# LPC11Uxx register map
File version: 7
CPU: CM0 r0p0, little endian, no MPU, no FPU, 2 interrupt priority bits
Registers are 32-bit, read-write, reset 0x0 unless marked. A register's access mark holds for its fields unless they carry their own. Offsets are from the block's base; [hi:lo] are bit positions; lines under a group give offsets from that group; {n}, {i} and the like mark numbered series; 'fields as' and 'values as' point back to an identical list.

## GPIO_GROUP_INT0 — GPIO group interrupt
Base 0x4005C000
Same registers: GPIO_GROUP_INT1 0x40060000
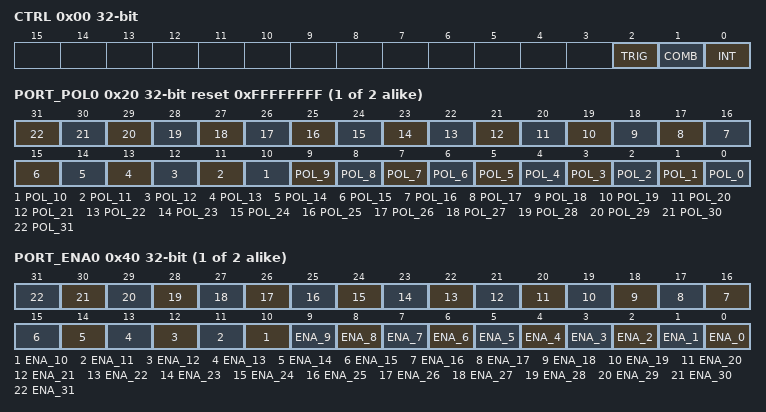
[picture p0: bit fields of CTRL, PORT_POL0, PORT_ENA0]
0x00 CTRL — GPIO grouped interrupt control register
  [2] TRIG — Group interrupt trigger
    0=EDGE_TRIGGERED; 1=LEVEL_TRIGGERED
  [1] COMB — Combine enabled inputs for group interrupt
    0=OR_FUNCTIONALITY_A_ (OR functionality: A grouped interrupt is generated when any one of the enabled inputs is active (based on its programmed polarity).); 1=AND_FUNCTIONALITY_A (AND functionality: An interrupt is generated when all enabled bits are active (based on their programmed polarity).)
  [0] INT — Group interrupt status. This bit is cleared by writing a one to it. Writing zero has no effect.
    0=NO_INTERRUPT_REQUEST (No interrupt request is pending.); 1=INTERRUPT_REQUEST_IS (Interrupt request is active.)
{0x20+4i} PORT_POL{i} (i=0..1) reset 0xFFFFFFFF — GPIO grouped interrupt port 0 polarity register
  [n] POL_{n} (n=1..31) — Configure pin polarity of port 0/1 pins for group interrupt. Bit n corresponds to pin P0/1_n of port 0/1. 0 = the pin is active LOW. If the level on this pin is LOW, the pin contributes to the group interrupt. 1 = the pin is active HIGH. If the level on this pin is HIGH, the pin contributes to the group interrupt.
  [0] POL_0 — Configure pin polarity of port pins for group interrupt. Bit n corresponds to pin P0/1_n of port 0/1 . 0 = the pin is active LOW. If the level on this pin is LOW, the pin contributes to the group interrupt. 1 = the pin is active HIGH. If the level on this pin is HIGH, the pin contributes to the group interrupt.
{0x40+4i} PORT_ENA{i} (i=0..1) — GPIO grouped interrupt port 0/1 enable register
  [n] ENA_{n} (n=0..31) — Enable port 0/1 pin for group interrupt. Bit n corresponds to pin P0/1_n of port 0/1. 0 = the port 0/1 pin is disabled and does not contribute to the grouped interrupt. 1 = the port 0/1 pin is enabled and contributes to the grouped interrupt.

## GPIO_PORT
Base 0x50000000
{0x0+i} B0{i} (i=0..31) 8-bit — Byte pin registers port 0; pins PIO0_0 to PIO0_31
  [0] PBYTE — Read: state of the pin P0_n, regardless of direction, masking, or alternate function, except that pins configured as analog I/O always read as 0. Write: loads the pin's output bit.
{0x0+i} B1{i} (i=32..63) 8-bit — Byte pin registers port 1
  [0] PBYTE — Read: state of the pin P1_n, regardless of direction, masking, or alternate function, except that pins configured as analog I/O always read as 0. Write: loads the pin's output bit.
{0x1000+4i} W_0{i} (i=0..31) — Word pin registers port 0
  [31:0] PWORD — Read 0: pin is LOW. Write 0: clear output bit. Read 0xFFFF FFFF: pin is HIGH. Write any value 0x0000 0001 to 0xFFFF FFFF: set output bit. Only 0 or 0xFFFF FFFF can be read. Writing any value other than 0 will set the output bit.
{0x1000+4i} W_1{i} (i=32..63) — Word pin registers port 1
  fields as W_00
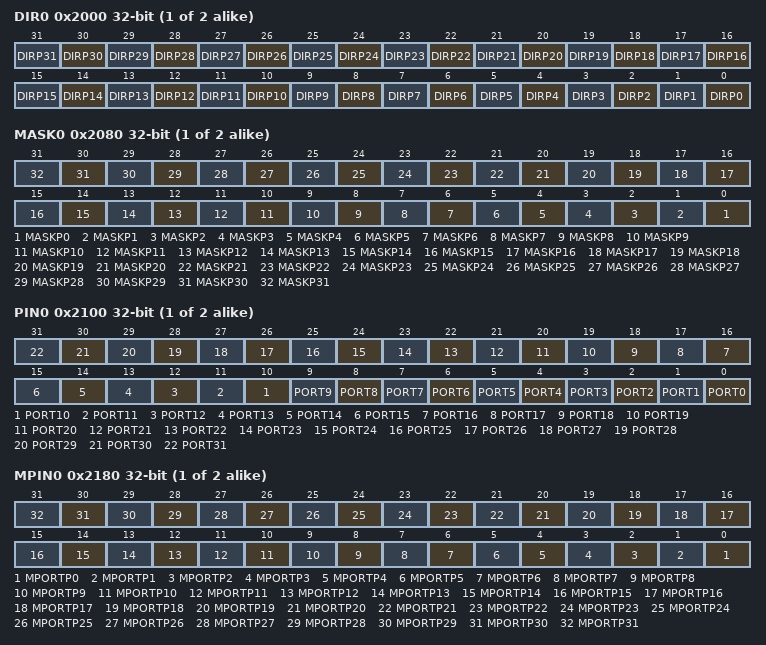
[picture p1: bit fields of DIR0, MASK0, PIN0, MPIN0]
{0x2000+4i} DIR{i} (i=0..1) — Direction registers port 0/1
  [n] DIRP{n} (n=0..31) — Selects pin direction for pin P0/1_n (bit 0 = P0/1_0, bit 1 = P0_1, ..., bit 31 = P0/1_31). 0 = input. 1 = output.
{0x2080+4i} MASK{i} (i=0..1) — Mask register port 0/1
  [n] MASKP{n} (n=0..31) — Controls which bits corresponding to P0/1_n are active in the P0/1 PIN register (bit 0 = P0/1_0, bit 1 = P0/1_1, ..., bit 31 = P0/1_31). 0 = Read MPORT: pin state; write MPORT: load output bit. 1 = Read MPORT: 0; write MPORT: output bit not affected.
{0x2100+4i} PIN{i} (i=0..1) — Portpin register port 0
  [n] PORT{n} (n=0..31) — Reads pin states or loads output bits (bit 0 = P0/1_0, bit 1 = P0/1_1, ..., bit 31 = P0/1_31). 0 = Read: pin is low; write: clear output bit. 1 = Read: pin is high; write: set output bit.
{0x2180+4i} MPIN{i} (i=0..1) — Masked port register port 0/1
  [n] MPORTP{n} (n=0..31) — Masked port register (bit 0 = P0/1_0, bit 1 = P0/1_1, ..., bit 31 = P0/1_31). 0 = Read: pin is LOW and/or the corresponding bit in the MASK register is 1; write: clear output bit if the corresponding bit in the MASK register is 0. 1 = Read: pin is HIGH and the corresponding bit in the MASK register is 0; write: set output bit if the corresponding bit in the MASK register is 0.
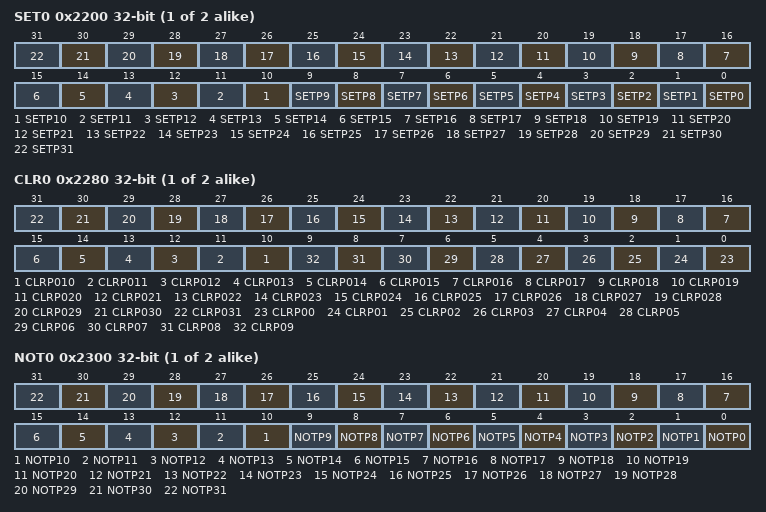
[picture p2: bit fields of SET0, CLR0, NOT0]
{0x2200+4i} SET{i} (i=0..1) — Write: Set register for port 0/1 Read: output bits for port 0/1
  [n] SETP{n} (n=0..31) — Read or set output bits. 0 = Read: output bit: write: no operation. 1 = Read: output bit; write: set output bit.
{0x2280+4i} CLR{i} (i=0..1) wo reset not defined — Clear port 0/1
  [n] CLRP{n:03} (n=10..31) — Clear output bits: 0 = No operation. 1 = Clear output bit.
  [n] CLRP{n:02} (n=0..9) — Clear output bits: 0 = No operation. 1 = Clear output bit.
{0x2300+4i} NOT{i} (i=0..1) wo reset not defined — Toggle port 0/1
  [n] NOTP{n} (n=0..31) — Toggle output bits: 0 = no operation. 1 = Toggle output bit.
